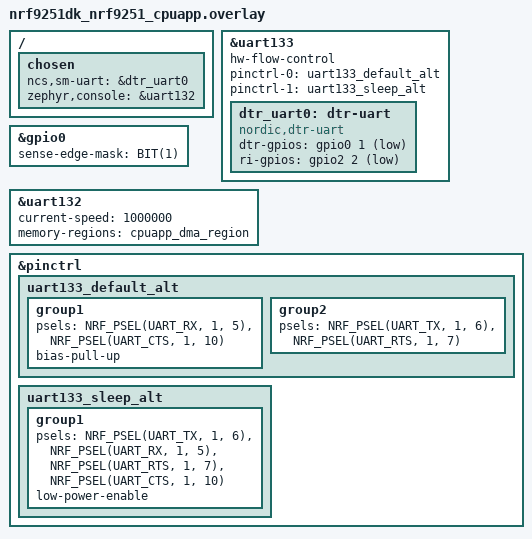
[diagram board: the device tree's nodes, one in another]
/*
 * Copyright (c) 2026 Nordic Semiconductor ASA
 *
 * SPDX-License-Identifier: LicenseRef-Nordic-5-Clause
 */

/ {
	chosen {
		ncs,sm-uart = &dtr_uart0;
		zephyr,console = &uart132;
	};
};

/* DTR with DK */
&uart133 {
	status = "okay";
	hw-flow-control;

	dtr_uart0: dtr-uart {
		compatible = "nordic,dtr-uart";
		dtr-gpios = <&gpio0 1 (GPIO_PULL_UP | GPIO_ACTIVE_LOW)>;
		ri-gpios = <&gpio2 2 GPIO_ACTIVE_LOW>;
		status = "okay";
	};

	pinctrl-0 = <&uart133_default_alt>;
	pinctrl-1 = <&uart133_sleep_alt>;
	pinctrl-names = "default", "sleep";
};

&gpio0 {
	status = "okay";
	/* Use PORT event for DTR (1) pin to save power */
	sense-edge-mask = <BIT(1)>;
};

/* Enable UART132 as the shared backend for Zephyr logs and modem traces.
 * Modem traces require 1 000 000 baud. Hardware flow control is not used.
 */
&uart132 {
	status = "okay";
	current-speed = <1000000>;
	memory-regions = <&cpuapp_dma_region>;
};

&pinctrl {
	uart133_default_alt: uart133_default_alt {
		group1 {
			psels = <NRF_PSEL(UART_RX, 1, 5)>,
				<NRF_PSEL(UART_CTS, 1, 10)>;
			bias-pull-up;
		};
		group2 {
			psels = <NRF_PSEL(UART_TX, 1, 6)>,
				<NRF_PSEL(UART_RTS, 1, 7)>;
		};
	};

	uart133_sleep_alt: uart133_sleep_alt {
		group1 {
			psels = <NRF_PSEL(UART_TX, 1, 6)>,
				<NRF_PSEL(UART_RX, 1, 5)>,
				<NRF_PSEL(UART_RTS, 1, 7)>,
				<NRF_PSEL(UART_CTS, 1, 10)>;
			low-power-enable;
		};
	};
};
